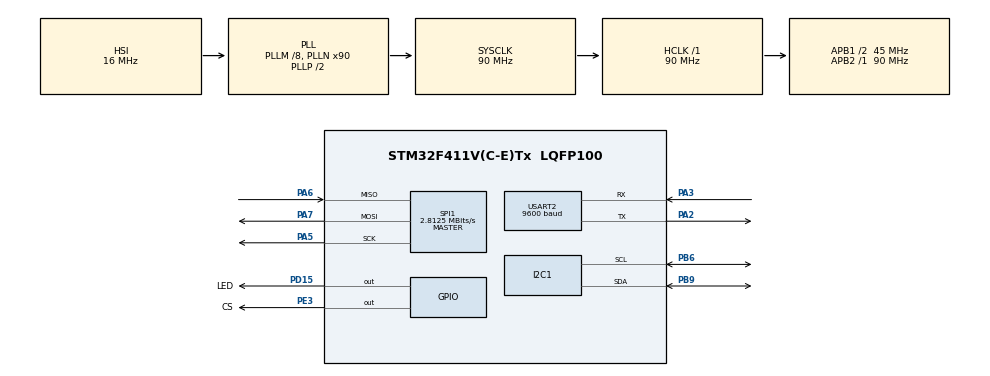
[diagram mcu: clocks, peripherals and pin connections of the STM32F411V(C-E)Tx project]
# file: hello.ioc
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Dma.Request0=USART2_RX
Dma.Request1=USART2_TX
Dma.USART2_RX.0.Direction=DMA_PERIPH_TO_MEMORY
Dma.USART2_RX.0.FIFOMode=DMA_FIFOMODE_DISABLE
Dma.USART2_RX.0.Instance=DMA1_Stream5
Dma.USART2_RX.0.MemDataAlignment=DMA_MDATAALIGN_BYTE
Dma.USART2_RX.0.MemInc=DMA_MINC_ENABLE
Dma.USART2_RX.0.Mode=DMA_NORMAL
Dma.USART2_RX.0.PeriphDataAlignment=DMA_PDATAALIGN_BYTE
Dma.USART2_RX.0.PeriphInc=DMA_PINC_DISABLE
Dma.USART2_RX.0.Priority=DMA_PRIORITY_HIGH
Dma.USART2_TX.1.Direction=DMA_MEMORY_TO_PERIPH
Dma.USART2_TX.1.FIFOMode=DMA_FIFOMODE_DISABLE
Dma.USART2_TX.1.Instance=DMA1_Stream6
Dma.USART2_TX.1.MemDataAlignment=DMA_MDATAALIGN_BYTE
Dma.USART2_TX.1.MemInc=DMA_MINC_ENABLE
Dma.USART2_TX.1.Mode=DMA_NORMAL
Dma.USART2_TX.1.PeriphDataAlignment=DMA_PDATAALIGN_BYTE
Dma.USART2_TX.1.PeriphInc=DMA_PINC_DISABLE
Dma.USART2_TX.1.Priority=DMA_PRIORITY_HIGH
I2C1.I2C_Mode=I2C_Fast
Mcu.Family=STM32F4
Mcu.Name=STM32F411V(C-E)Tx
Mcu.Package=LQFP100
NVIC.DMA1_Stream5_IRQn=true\:0\:0\:false\:false\:true\:false\:true
NVIC.DMA1_Stream6_IRQn=true\:0\:0\:false\:false\:true\:false\:true
NVIC.PriorityGroup=NVIC_PRIORITYGROUP_4
NVIC.SPI1_IRQn=true\:0\:0\:false\:false\:true\:true\:true
NVIC.TIM1_UP_TIM10_IRQn=true\:0\:0\:false\:false\:true\:true\:true
NVIC.USART2_IRQn=true\:0\:0\:false\:false\:true\:true\:true
PA2.Mode=Asynchronous
PA2.Signal=USART2_TX
PA3.Mode=Asynchronous
PA3.Signal=USART2_RX
PA5.Mode=Full_Duplex_Master
PA5.Signal=SPI1_SCK
PA6.Mode=Full_Duplex_Master
PA6.Signal=SPI1_MISO
PA7.Mode=Full_Duplex_Master
PA7.Signal=SPI1_MOSI
PB6.Mode=I2C
PB6.Signal=I2C1_SCL
PB9.Mode=I2C
PB9.Signal=I2C1_SDA
PD15.GPIO_Label=LED
PD15.Signal=GPIO_Output
PE3.GPIO_Label=CS
PE3.Signal=GPIO_Output
ProjectManager.HeapSize=0x200
ProjectManager.StackSize=0x400
ProjectManager.TargetToolchain=STM32CubeIDE
RCC.48MHZClocksFreq_Value=45000000
RCC.AHBFreq_Value=90000000
RCC.APB1CLKDivider=RCC_HCLK_DIV2
RCC.APB1Freq_Value=45000000
RCC.APB1TimFreq_Value=90000000
RCC.APB2Freq_Value=90000000
RCC.APB2TimFreq_Value=90000000
RCC.CortexFreq_Value=90000000
RCC.HCLKFreq_Value=90000000
RCC.HSE_VALUE=25000000
RCC.HSI_VALUE=16000000
RCC.LSE_VALUE=32768
RCC.PLLM=8
RCC.PLLN=90
RCC.SYSCLKFreq_VALUE=90000000
RCC.SYSCLKSource=RCC_SYSCLKSOURCE_PLLCLK
RCC.VCOOutputFreq_Value=180000000
SPI1.BaudRatePrescaler=SPI_BAUDRATEPRESCALER_32
SPI1.CalculateBaudRate=2.8125 MBits/s
SPI1.Direction=SPI_DIRECTION_2LINES
SPI1.Mode=SPI_MODE_MASTER
SPI1.VirtualType=VM_MASTER
TIM10.AutoReloadPreload=TIM_AUTORELOAD_PRELOAD_ENABLE
TIM10.Period=17999
TIM10.Prescaler=49
USART2.BaudRate=9600
USART2.VirtualMode=VM_ASYNC
VP_TIM10_VS_ClockSourceINT.Mode=Enable_Timer
board=custom

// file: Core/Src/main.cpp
/* USER CODE BEGIN Header */
/**
  ******************************************************************************
  * @file           : main.c
  * @brief          : Main program body
  ******************************************************************************
  * @attention
  *
  * <h2><center>&copy; Copyright (c) 2020 STMicroelectronics.
  * All rights reserved.</center></h2>
  *
  * This software component is licensed by ST under BSD 3-Clause license,
  * the "License"; You may not use this file except in compliance with the
  * License. You may obtain a copy of the License at:
  *                        opensource.org/licenses/BSD-3-Clause
  *
  ******************************************************************************
  */
/* USER CODE END Header */

#include "main.h"

/* USER CODE BEGIN Includes */
#include <stdio.h>
#include "mainpp.h"
/* USER CODE END Includes */

I2C_HandleTypeDef hi2c1;

SPI_HandleTypeDef hspi1;

TIM_HandleTypeDef htim10;

UART_HandleTypeDef huart2;
DMA_HandleTypeDef hdma_usart2_rx;
DMA_HandleTypeDef hdma_usart2_tx;

/* USER CODE BEGIN PV */
int licznik = 0;
/* USER CODE END PV */

void SystemClock_Config(void);
static void MX_GPIO_Init(void);
static void MX_DMA_Init(void);
static void MX_USART2_UART_Init(void);
static void MX_I2C1_Init(void);
static void MX_TIM10_Init(void);
static void MX_SPI1_Init(void);

int main(void)
{

  /* MCU Configuration--------------------------------------------------------*/

  /* Reset of all peripherals, Initializes the Flash interface and the Systick. */
  HAL_Init();

  /* Configure the system clock */
  SystemClock_Config();

  /* Initialize all configured peripherals */
  MX_GPIO_Init();
  MX_DMA_Init();
  MX_USART2_UART_Init();
  MX_I2C1_Init();
  MX_TIM10_Init();
  MX_SPI1_Init();
  /* USER CODE BEGIN 2 */
  setup();
  initialize();

  /* USER CODE END 2 */

  /* Infinite loop */
  /* USER CODE BEGIN WHILE */
  while (1)
  {
	  Napraw_Blad(30);
	  Calculate();
	  ++licznik;
	  if(licznik == 19){
		licznik = 0;
		Wez_pozycje();
		HAL_GPIO_TogglePin(GPIOD, GPIO_PIN_15);
	  }
	  HAL_Delay(10);

    /* USER CODE END WHILE */

  }
}

void SystemClock_Config(void)
{
  RCC_OscInitTypeDef RCC_OscInitStruct = {0};
  RCC_ClkInitTypeDef RCC_ClkInitStruct = {0};

  /** Configure the main internal regulator output voltage
  */
  __HAL_RCC_PWR_CLK_ENABLE();
  __HAL_PWR_VOLTAGESCALING_CONFIG(PWR_REGULATOR_VOLTAGE_SCALE1);
  /** Initializes the CPU, AHB and APB busses clocks
  */
  RCC_OscInitStruct.OscillatorType = RCC_OSCILLATORTYPE_HSI;
  RCC_OscInitStruct.HSIState = RCC_HSI_ON;
  RCC_OscInitStruct.HSICalibrationValue = RCC_HSICALIBRATION_DEFAULT;
  RCC_OscInitStruct.PLL.PLLState = RCC_PLL_ON;
  RCC_OscInitStruct.PLL.PLLSource = RCC_PLLSOURCE_HSI;
  RCC_OscInitStruct.PLL.PLLM = 8;
  RCC_OscInitStruct.PLL.PLLN = 90;
  RCC_OscInitStruct.PLL.PLLP = RCC_PLLP_DIV2;
  RCC_OscInitStruct.PLL.PLLQ = 4;
  if (HAL_RCC_OscConfig(&RCC_OscInitStruct) != HAL_OK)
  {
    Error_Handler();
  }
  /** Initializes the CPU, AHB and APB busses clocks
  */
  RCC_ClkInitStruct.ClockType = RCC_CLOCKTYPE_HCLK|RCC_CLOCKTYPE_SYSCLK
                              |RCC_CLOCKTYPE_PCLK1|RCC_CLOCKTYPE_PCLK2;
  RCC_ClkInitStruct.SYSCLKSource = RCC_SYSCLKSOURCE_PLLCLK;
  RCC_ClkInitStruct.AHBCLKDivider = RCC_SYSCLK_DIV1;
  RCC_ClkInitStruct.APB1CLKDivider = RCC_HCLK_DIV2;
  RCC_ClkInitStruct.APB2CLKDivider = RCC_HCLK_DIV1;

  if (HAL_RCC_ClockConfig(&RCC_ClkInitStruct, FLASH_LATENCY_2) != HAL_OK)
  {
    Error_Handler();
  }
}

static void MX_I2C1_Init(void)
{

  hi2c1.Instance = I2C1;
  hi2c1.Init.ClockSpeed = 400000;
  hi2c1.Init.DutyCycle = I2C_DUTYCYCLE_2;
  hi2c1.Init.OwnAddress1 = 0;
  hi2c1.Init.AddressingMode = I2C_ADDRESSINGMODE_7BIT;
  hi2c1.Init.DualAddressMode = I2C_DUALADDRESS_DISABLE;
  hi2c1.Init.OwnAddress2 = 0;
  hi2c1.Init.GeneralCallMode = I2C_GENERALCALL_DISABLE;
  hi2c1.Init.NoStretchMode = I2C_NOSTRETCH_DISABLE;
  if (HAL_I2C_Init(&hi2c1) != HAL_OK)
  {
    Error_Handler();
  }

}

static void MX_SPI1_Init(void)
{

  /* SPI1 parameter configuration*/
  hspi1.Instance = SPI1;
  hspi1.Init.Mode = SPI_MODE_MASTER;
  hspi1.Init.Direction = SPI_DIRECTION_2LINES;
  hspi1.Init.DataSize = SPI_DATASIZE_8BIT;
  hspi1.Init.CLKPolarity = SPI_POLARITY_LOW;
  hspi1.Init.CLKPhase = SPI_PHASE_1EDGE;
  hspi1.Init.NSS = SPI_NSS_SOFT;
  hspi1.Init.BaudRatePrescaler = SPI_BAUDRATEPRESCALER_32;
  hspi1.Init.FirstBit = SPI_FIRSTBIT_MSB;
  hspi1.Init.TIMode = SPI_TIMODE_DISABLE;
  hspi1.Init.CRCCalculation = SPI_CRCCALCULATION_DISABLE;
  hspi1.Init.CRCPolynomial = 10;
  if (HAL_SPI_Init(&hspi1) != HAL_OK)
  {
    Error_Handler();
  }

}

static void MX_TIM10_Init(void)
{

  htim10.Instance = TIM10;
  htim10.Init.Prescaler = 49;
  htim10.Init.CounterMode = TIM_COUNTERMODE_UP;
  htim10.Init.Period = 17999;
  htim10.Init.ClockDivision = TIM_CLOCKDIVISION_DIV1;
  htim10.Init.AutoReloadPreload = TIM_AUTORELOAD_PRELOAD_ENABLE;
  if (HAL_TIM_Base_Init(&htim10) != HAL_OK)
  {
    Error_Handler();
  }

}

static void MX_USART2_UART_Init(void)
{

  huart2.Instance = USART2;
  huart2.Init.BaudRate = 9600;
  huart2.Init.WordLength = UART_WORDLENGTH_8B;
  huart2.Init.StopBits = UART_STOPBITS_1;
  huart2.Init.Parity = UART_PARITY_NONE;
  huart2.Init.Mode = UART_MODE_TX_RX;
  huart2.Init.HwFlowCtl = UART_HWCONTROL_NONE;
  huart2.Init.OverSampling = UART_OVERSAMPLING_16;
  if (HAL_UART_Init(&huart2) != HAL_OK)
  {
    Error_Handler();
  }

}

static void MX_DMA_Init(void)
{

  /* DMA controller clock enable */
  __HAL_RCC_DMA1_CLK_ENABLE();

  /* DMA interrupt init */
  /* DMA1_Stream5_IRQn interrupt configuration */
  HAL_NVIC_SetPriority(DMA1_Stream5_IRQn, 0, 0);
  HAL_NVIC_EnableIRQ(DMA1_Stream5_IRQn);
  /* DMA1_Stream6_IRQn interrupt configuration */
  HAL_NVIC_SetPriority(DMA1_Stream6_IRQn, 0, 0);
  HAL_NVIC_EnableIRQ(DMA1_Stream6_IRQn);

}

static void MX_GPIO_Init(void)
{
  GPIO_InitTypeDef GPIO_InitStruct = {0};

  /* GPIO Ports Clock Enable */
  __HAL_RCC_GPIOE_CLK_ENABLE();
  __HAL_RCC_GPIOA_CLK_ENABLE();
  __HAL_RCC_GPIOD_CLK_ENABLE();
  __HAL_RCC_GPIOB_CLK_ENABLE();

  /*Configure GPIO pin Output Level */
  HAL_GPIO_WritePin(CS_GPIO_Port, CS_Pin, GPIO_PIN_RESET);

  /*Configure GPIO pin Output Level */
  HAL_GPIO_WritePin(LED_GPIO_Port, LED_Pin, GPIO_PIN_RESET);

  /*Configure GPIO pin : CS_Pin */
  GPIO_InitStruct.Pin = CS_Pin;
  GPIO_InitStruct.Mode = GPIO_MODE_OUTPUT_PP;
  GPIO_InitStruct.Pull = GPIO_NOPULL;
  GPIO_InitStruct.Speed = GPIO_SPEED_FREQ_LOW;
  HAL_GPIO_Init(CS_GPIO_Port, &GPIO_InitStruct);

  /*Configure GPIO pin : LED_Pin */
  GPIO_InitStruct.Pin = LED_Pin;
  GPIO_InitStruct.Mode = GPIO_MODE_OUTPUT_PP;
  GPIO_InitStruct.Pull = GPIO_NOPULL;
  GPIO_InitStruct.Speed = GPIO_SPEED_FREQ_LOW;
  HAL_GPIO_Init(LED_GPIO_Port, &GPIO_InitStruct);

}

void Error_Handler(void)
{
}

/************************ (C) COPYRIGHT STMicroelectronics *****END OF FILE****/
